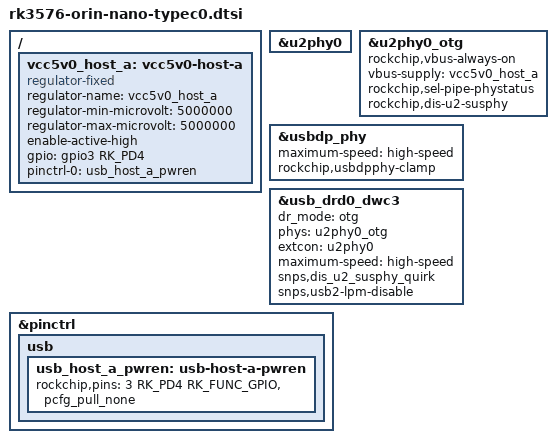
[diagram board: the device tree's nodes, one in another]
// SPDX-License-Identifier: (GPL-2.0+ OR MIT)
/*
 * Guangzhou Easy EAI Technology Co., Ltd.
 *
 */

/ {
	vcc5v0_host_a: vcc5v0-host-a {
		compatible = "regulator-fixed";
		regulator-name = "vcc5v0_host_a";
		regulator-min-microvolt = <5000000>;
		regulator-max-microvolt = <5000000>;
		enable-active-high;
		gpio = <&gpio3 RK_PD4 GPIO_ACTIVE_HIGH>;
		pinctrl-names = "default";
		pinctrl-0 = <&usb_host_a_pwren>;
	};
};

/* PHY */
&u2phy0 {
	status = "okay";
};

&u2phy0_otg {
	status = "okay";
	rockchip,vbus-always-on;
	vbus-supply = <&vcc5v0_host_a>;
	rockchip,sel-pipe-phystatus;
	rockchip,dis-u2-susphy;
};

&usbdp_phy {
	//rockchip,dp-lane-mux = <2 3>;
	maximum-speed = "high-speed";
	rockchip,usbdpphy-clamp;
	status = "okay";
};



/* 控制器 */
&usb_drd0_dwc3 {
	dr_mode = "otg";
	phys = <&u2phy0_otg>;
	phy-names = "usb2-phy";
	extcon = <&u2phy0>;
	maximum-speed = "high-speed";
	snps,dis_u2_susphy_quirk;
	snps,usb2-lpm-disable;
	status = "okay";
};

&pinctrl {
	usb {
		usb_host_a_pwren: usb-host-a-pwren {
			rockchip,pins = <3 RK_PD4 RK_FUNC_GPIO &pcfg_pull_none>;
		};
	};	
};


